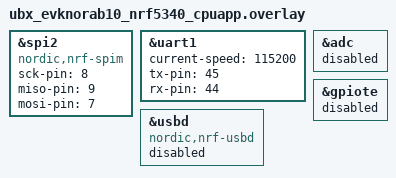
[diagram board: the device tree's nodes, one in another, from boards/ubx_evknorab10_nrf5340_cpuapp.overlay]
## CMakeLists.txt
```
#
# Copyright (c) 2018 Nordic Semiconductor
#
# SPDX-License-Identifier: LicenseRef-Nordic-5-Clause
#
cmake_minimum_required(VERSION 3.13.1)

# list(APPEND mcuboot_OVERLAY_CONFIG
#   "${CMAKE_CURRENT_SOURCE_DIR}/child_image/mcuboot.conf"
#   )

# list(APPEND netboot_OVERLAY_CONFIG
#   "${CMAKE_CURRENT_SOURCE_DIR}/child_image/netboot.conf"
#   )

find_package(Zephyr REQUIRED HINTS $ENV{ZEPHYR_BASE})
project(NONE)

# NORDIC SDK APP START
zephyr_library_include_directories(.)
zephyr_library_include_directories(../movus_lib)
target_sources(app PRIVATE 
    src/main.c 
    ../movus_lib/hal/hal_spi.c 
    ../movus_lib/peripheral/lis3mdl.c 
    ../movus_lib/hal/ble.c
    ../movus_lib/hal/wdt.c
    ../movus_lib/hal/radio.c
    ../movus_lib/hal/hal_uart.c
    src/sample.c
    )

# NORDIC SDK APP END
```

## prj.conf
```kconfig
#
# Copyright (c) 2018 Nordic Semiconductor
#
# SPDX-License-Identifier: LicenseRef-Nordic-5-Clause
#
CONFIG_PM=y
#CONFIG_PM_DEEP_SLEEP_STATES=y  #WRC what is change since V1.5.1

# Required to disable default behavior of deep sleep on timeout
CONFIG_PM_DEVICE=y
CONFIG_GPIO=y 
CONFIG_SPI=y
CONFIG_I2C=n

CONFIG_WATCHDOG=y
CONFIG_UART_INTERRUPT_DRIVEN=y
# CONFIG_UART_ASYNC_API=y
# CONFIG_NRFX_UARTE0=y
CONFIG_HEAP_MEM_POOL_SIZE=100000

CONFIG_BT=y
CONFIG_BT_PERIPHERAL=y
CONFIG_BT_DEVICE_NAME="FitPower"
CONFIG_BT_DEVICE_APPEARANCE=833
CONFIG_BT_MAX_CONN=1 
# Enable the NUS service
CONFIG_BT_NUS=y
# CONFIG_BT_THROUGHPUT=y

CONFIG_BT_USER_DATA_LEN_UPDATE=y
CONFIG_BT_USER_PHY_UPDATE=y
CONFIG_BT_GAP_AUTO_UPDATE_CONN_PARAMS=y

## Debugging
# CONFIG_CONSOLE=n
# CONFIG_UART_CONSOLE=n
# CONFIG_LOG=n
# CONFIG_SERIAL=n
# CONFIG_USE_SEGGER_RTT=n
# CONFIG_LOG_BACKEND_RTT=n
# CONFIG_LOG_BACKEND_UART=n
CONFIG_CONSOLE=y
CONFIG_UART_CONSOLE=y
CONFIG_LOG=y
CONFIG_SERIAL=y
CONFIG_USE_SEGGER_RTT=n
CONFIG_LOG_BACKEND_RTT=n
CONFIG_LOG_BACKEND_UART=y
CONFIG_FITPOWER_SERIAL_SAMPLING=y

CONFIG_CBPRINTF_FP_SUPPORT=y

CONFIG_WATCHDOG_DURATION=900000

CONFIG_BT_GATT_CLIENT=y
CONFIG_BT_ATT_PREPARE_COUNT=2
CONFIG_BT_CONN_TX_MAX=15
CONFIG_BT_L2CAP_TX_BUF_COUNT=15
CONFIG_BT_L2CAP_DYNAMIC_CHANNEL=y
CONFIG_BT_CTLR_PHY_2M=y
CONFIG_BT_CTLR_RX_BUFFERS=2
CONFIG_BT_BUF_ACL_TX_COUNT=10
CONFIG_BT_BUF_ACL_TX_SIZE=251
CONFIG_BT_CTLR_DATA_LENGTH_MAX=251

CONFIG_BT_AUTO_PHY_UPDATE=y

CONFIG_NEWLIB_LIBC=y

# CONFIG_BT_CTLR_ADVANCED_FEATURES=y
# CONFIG_BT_CTLR_CONN_RSSI=y


# CONFIG_CLOCK_CONTROL_NRF_K32SRC_RC=y
# CONFIG_CLOCK_CONTROL_NRF_K32SRC_XTAL=n
# CONFIG_BOARD_ENABLE_DCDC_APP=n
# CONFIG_BOARD_ENABLE_DCDC_NET=n
CONFIG_BOARD_ENABLE_DCDC_HV=n

# Thread analysis
# CONFIG_THREAD_ANALYZER=y
# CONFIG_THREAD_NAME=y

# Enable mcumgr.
CONFIG_MCUMGR=y
CONFIG_MCUBOOT_IMAGE_VERSION="0.0.4" # +3dB Tx Power

# Enable most core commands.
CONFIG_MCUMGR_CMD_IMG_MGMT=y
CONFIG_MCUMGR_CMD_OS_MGMT=y

# # Ensure an MCUboot-compatible binary is generated.
CONFIG_BOOTLOADER_MCUBOOT=y

# Allow for large Bluetooth data packets.
CONFIG_BT_L2CAP_TX_MTU=498
CONFIG_BT_BUF_ACL_RX_SIZE=502
CONFIG_MCUMGR_BUF_SIZE=634

# Enable the Bluetooth (unauthenticated) and shell mcumgr transports.
CONFIG_MCUMGR_SMP_BT=y
CONFIG_MCUMGR_SMP_BT_AUTHEN=n

# Some command handlers require a large stack.
CONFIG_SYSTEM_WORKQUEUE_STACK_SIZE=4096
```

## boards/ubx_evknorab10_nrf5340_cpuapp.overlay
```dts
&spi2 {
	compatible = "nordic,nrf-spim";
	status = "okay";
	sck-pin = <8>;  // original 8
	miso-pin = <9>;  // original 9
	mosi-pin = <7>;  // original 10
};

// /{
// 	leds {
// 		compatible = "gpio-leds";
// 		led0: led_0 {
// 			gpios = <&gpio0 30 GPIO_ACTIVE_HIGH>;
// 			label = "BLE LED";
// 		};

// 		led1: led_1 {
// 			gpios = <&gpio0 31 GPIO_ACTIVE_HIGH>;
// 			label = "DEBUG LED";
// 		};
// 	};
// };

&uart1{
	status = "okay";
	current-speed = <115200>;
	tx-pin = <45>;
	rx-pin = <44>;
};


&usbd {
	compatible = "nordic,nrf-usbd";
	status = "disabled";
};

&adc {
	status = "disabled";
};

&gpiote {
	status = "disabled";
};

// &pwm0 {
// 	status = "disabled"
// }

// &timer1 {
// 	status = "disabled"
// }

// &timer2 {
// 	status = "disabled"
// }

// &qspi {
// 	status = "disabled"
// }
```

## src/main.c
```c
#include <soc.h>
#include <stdio.h>
#include <zephyr.h>
#include <zephyr/types.h>
#include <string.h>
#include <logging/log.h>
#include <drivers/spi.h> 
#include "peripheral/lis3mdl.h"
#include "hal/hal_spi.h"
#include "hal/hal_uart.h"
#include "hal/ble.h"
#include <stdbool.h>
#include <stdio.h>
#include <math.h>
#include <stdlib.h>
#include "ble_transfer.h"
#include "sample.h"
#include "hal/wdt.h"
#include "hal/radio.h"
#include <pm/pm.h>

#define LOG_MODULE_NAME fittag
LOG_MODULE_REGISTER(LOG_MODULE_NAME);
void main(void)
{
	// install_watchdog();
	hal_spi_init();
#if CONFIG_FITPOWER_SERIAL_SAMPLING
	hal_uart_init();
#else
	ble_init();
	k_sem_give(&sample_ok);
	// tx_pwr_init();
#endif
	// lis3mdl_validation();
	// sensoroff(0);
	pm_device_state_set(spi, PM_DEVICE_STATE_LOW_POWER,NULL,NULL);
}
```

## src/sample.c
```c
#include <string.h>
#include <zephyr/types.h>
#include <sys/byteorder.h>
#include "sample.h"
#include "peripheral/lis3mdl.h"
#include "hal/ble.h"
#include "hal/hal_spi.h"
#include "hal/hal_uart.h"
#include <logging/log.h>

#define LOG_MODULE_NAME sampling
LOG_MODULE_REGISTER(LOG_MODULE_NAME);

#define THROUGH_PACKET_SIZE 50
struct k_fifo fifo_stream;
struct k_sem stream_sem;
void sensor_mode(uint8_t mode) {

	for (int i=0; i < NUM_SENSOR; i++) {
		switch (mode)
		{
		case 0:
			lis3mdl_poweroff(spi_group[i].spi_ctg);
			k_msleep(20);
			break;
		case 1:
			lis3mdl_init(spi_group[i].spi_ctg);
			k_msleep(20);
			break;
		// case 2:
		// 	lis3mdl_powerlow(spi_ctg);
		// 	k_msleep(20);
		default:
			break;
		}
	}
}

void streaming_data() {
	struct stream_data_t *stream;
	struct sensor_data_t magnet;
	magnet.sensor_id = 0;
	uint32_t temp_time = k_cyc_to_us_floor32(k_cycle_get_32());
	if (k_cyc_to_us_floor32(k_cycle_get_32()) - temp_time > 999) {
		lis3mdl_get_xyz(spi_group[0].spi_ctg, &magnet);
		magnet.timestamp = temp_time; // get timestamp in microseconds 
	}
	stream = k_malloc(sizeof(*stream));
	stream->data = magnet;
	stream->len = sizeof(magnet);

	k_fifo_put(&fifo_stream, stream);
}

/*
 * Print a null-terminated string character by character to the UART interface
 */
void print_uart(char *buf)
{
	int msg_len = strlen(buf);

	for (int i = 0; i < msg_len; i++) {
		uart_poll_out(uart, buf[i]);
	}
}


void transfer(struct sensor_data_t *data, uint16_t count) {

	static char buf[50];
    uint32_t send_count = 0;
    int err;
    uint32_t send_count_uplimit = count;
	uint8_t err_tick;

	err_tick = 0; // Check connection is still there
	uint32_t start = k_uptime_get_32();
    while(send_count < send_count_uplimit){
		memset(buf,0,sizeof(buf));
		sprintf(buf, "%d %u %u %u %u\r\n",data[send_count].sensor_id, data[send_count].x_value, data[send_count].y_value, data[send_count].z_value,  data[send_count].timestamp);
		print_uart(buf);
		send_count++;
    }
	uint32_t end = k_uptime_get_32() - start;
	LOG_INF("Write time:%u", end);
	// Send acknoledge when data is done transferring
	memset(buf,0,sizeof(buf));
	sprintf(buf, "0\n");
	print_uart(buf);
	if (err) {
            LOG_WRN("Failed to send data over BLE connection");
    }
}

void ble_transfer(struct sensor_data_t *data, uint16_t count) {

	static char buf[THROUGH_PACKET_SIZE];
    uint32_t send_count = 0;
    int err;
    uint32_t send_count_uplimit = count;
	uint8_t err_tick;

	sent_cnt = 0; // clear sent counting
	err_tick = 0; // Check connection is still there
	uint32_t start = k_uptime_get_32();
    while(send_count < send_count_uplimit){
		memset(buf,0,sizeof(buf));
		sprintf(buf, "%d %u %u %u %u\n",data[send_count].sensor_id, 
				data[send_count].x_value, 
				data[send_count].y_value, 
				data[send_count].z_value,  
				data[send_count].timestamp);
		if (err_tick > 200) {

			// force disconnect from gateway if data cant send after a few tries, more functionalities can be added here
			// IE: fs for unsent data 
			bt_conn_disconnect(current_conn ,BT_HCI_ERR_REMOTE_USER_TERM_CONN);
			break;  
		}
        err = bt_nus_send(NULL, buf, sizeof(buf));
        if (err) {
            LOG_WRN("Failed to send data over BLE connection");
			err_tick++;
        }
        else {
            send_count++;
        }

        if(send_count - get_sent_cnt() > (CONFIG_BT_L2CAP_TX_BUF_COUNT)){
             LOG_WRN("Buffer getting tight, wait sometime here");
             k_sleep(K_MSEC(3));
        }
    }
	uint32_t end = k_uptime_get_32() - start;
	LOG_INF("BLE write time:%u", end);
	// Send acknoledge when data is done transferring
	memset(buf,0,sizeof(buf));
	sprintf(buf, "0\n");
	err = bt_nus_send(NULL, buf, sizeof(buf));
	if (err) {
            LOG_WRN("Failed to send data over BLE connection");
    }
	// bt_conn_disconnect(current_conn ,BT_HCI_ERR_REMOTE_USER_TERM_CONN);
}

void check_sensor() {

	for (int i=0; i < NUM_SENSOR; i++) {
		
		if (lis3mdl_present(spi_group[i].spi_ctg)) {
			// LOG_INF("SENSOR %d present", i);
			spi_group[i].state = 1; // sensor is present
			// k_sleep(K_MSEC(1));
		}
	}
}

void sample_data(uint16_t count) {
	
	struct sensor_data_t *magnet;
	magnet = k_malloc(sizeof(struct sensor_data_t) * count);
	struct sensor_data_t junk;
	uint8_t id, count_temp, row, offsetlimit, ret = 0;
	uint8_t tries = 3;
	int sampled = 0;
	uint8_t order[NUM_SENSOR], new_order[NUM_SENSOR];
	
	sensor_mode(1); // turn on all sensors
	check_sensor();

	for (int i=0; i<NUM_SENSOR; i++) { // get default order (ie:1,2,3,4,5,6,7)
		order[i] = spi_group[i].sensor_id;
	}

	for (int i=0; i < NUM_SENSOR; i++) {
		// LOG_INF("Sensor %d PIN: %d", i, spi_group[i].spi_ctg.cs->gpio_pin);
		lis3mdl_get_xyz(spi_group[i].spi_ctg, &junk);
		if (junk.x_value == junk.y_value && junk.x_value == junk.z_value) {
			spi_group[i].state = 2;
		}
	}
	
	for (int i=0; i < count; i++) {
        if (count_temp == NUM_SENSOR) {
            count_temp = 0;
        }
		// lis3mdl_poweron(spi_ctg);
		// id = spi_group[count_temp].cs->gpio_pin - 4; // Hard-coded value, not optimized , change this 
		// LOG_INF("sampling sensor %d", spi_ctgx[count_temp].cs->gpio_pin);
		magnet[i].sensor_id = spi_group[count_temp].sensor_id;
		if (spi_group[count_temp].state == 1) {
			while(1) {
				uint32_t temp_time = k_cyc_to_us_floor32(k_cycle_get_32());
				if (i < NUM_SENSOR) {
					lis3mdl_get_xyz(spi_group[count_temp].spi_ctg, &(magnet[i]));
					magnet[i].timestamp = temp_time;
					break;
				}

				else if (temp_time - magnet[i-(NUM_SENSOR)].timestamp > 999) {
					lis3mdl_get_xyz(spi_group[count_temp].spi_ctg, &(magnet[i]));
					magnet[i].timestamp = temp_time; // get timestamp in microseconds 
					break;
				}
			}
		}

		// lis3mdl_powerlow(spi_ctg);
		count_temp++;
	}

	sensor_mode(0); // turn off all sensors
#if CONFIG_FITPOWER_SERIAL_SAMPLING
	transfer(magnet, count);
#else
	ble_transfer(magnet, count);
#endif
	k_free(magnet);
}

static uint8_t process_uart_command(char *buf, struct command_t *command) {
	char string[20]; // string test
	uint16_t count;
	LOG_INF("Command received: %s", string);
	char *token;
	char *rest = buf;
	char **array = (char**)k_malloc(3*sizeof(char*));
	for (int j=0; j < 3; j++)
		array[j] = (char*) k_malloc(sizeof(char)*10);

	int i = 0;
	while((token = strtok_r(rest, " ", &rest))) {
		strcpy(array[i], token);
		i++;
		if (i > 2) {
			break;
		}
	}
	if (strcmp("sample", array[0]) == 0) {
        command->mode = FULL_SAMPLE;
        command->samples = atoi(array[1]);
		return 0;
    } else if (strcmp("real", array[0]) == 0) {
        command->mode = REALTIME_SAMPLE;
        command->samples = 0;
		return 0;
    } else if (strcmp("check", array[0]) == 0) {
        command->mode = VALIDATION;
        command->samples = 0;
		return 0;
    }
	return 1;
}

static uint8_t process_command(struct uart_data_t *buf, struct command_t *command) {
	char string[51]; // string test
	memcpy(string, buf->data, sizeof(buf->data));
	string[sizeof(buf->data)] = '\0';
	LOG_INF("Command received: %s", log_strdup(string));
	char *token;
	char *rest = string;
	char **array = (char**)k_malloc(3*sizeof(char*));
	for (int j=0; j < 3; j++)
		array[j] = (char*) k_malloc(sizeof(char)*10);

	int i = 0;
	while((token = strtok_r(rest, " ", &rest))) {
		strcpy(array[i], token);
		i++;
		if (i > 2) {
			break;
		}
	}

    if (strcmp("sample", array[0]) == 0) {
        command->mode = FULL_SAMPLE;
        command->samples = atoi(array[1]);
		return 0;
    } else if (strcmp("real", array[0]) == 0) {
        command->mode = REALTIME_SAMPLE;
        command->samples = 0;
		return 0;
    } else if (strcmp("check", array[0]) == 0) {
        command->mode = VALIDATION;
        command->samples = 0;
		return 0;
    }
	return 1;
}

void sampling_thread() {
#if CONFIG_FITPOWER_SERIAL_SAMPLING
	char tx_buf[MSG_SIZE];
	k_sem_take(&sample_ok, K_FOREVER);
#else
	k_fifo_init(&fifo_stream);
	k_sem_init(&stream_sem, 0 , 1);
    k_sem_take(&ble_init_ok, K_FOREVER);
#endif
    // k_sem_take(&throughput_sem, K_FOREVER);
    for(;;) {
		struct command_t command;
#if CONFIG_FITPOWER_SERIAL_SAMPLING
		k_msgq_get(&uart_msgq, &tx_buf, K_FOREVER);
		if (!process_command(tx_buf, &command)) {
			switch (command.mode)
			{
			case FULL_SAMPLE:
				LOG_INF("Taking %d samples.", command.samples);
				sample_data(command.samples);
				break;
			case REALTIME_SAMPLE:
				LOG_INF("Sampling in realtime.");
				k_sem_give(&stream_sem);
				streaming_data();
				break;
			case VALIDATION:
				lis3mdl_validation();
				break;
			default:
				break;
			}
		}
#else
        struct uart_data_t *buf = k_fifo_get(&fifo_transfer,
							K_FOREVER);
        k_sem_take(&throughput_sem, K_FOREVER);
		if (!process_command(buf, &command)) {
			switch (command.mode)
			{
			case FULL_SAMPLE:
				LOG_INF("Taking %d samples.", command.samples);
				sample_data(command.samples);
				break;
			case REALTIME_SAMPLE:
				LOG_INF("Sampling in realtime.");
				k_sem_give(&stream_sem);
				streaming_data();
				break;
			case VALIDATION:
				lis3mdl_validation();
				break;
			default:
				break;
			}
		}
		k_free(buf);
#endif
    }
}

K_THREAD_DEFINE(sampling_thread_id, STACKSIZE, sampling_thread, NULL, NULL,
		NULL, PRIORITY, 0, 0);
```
